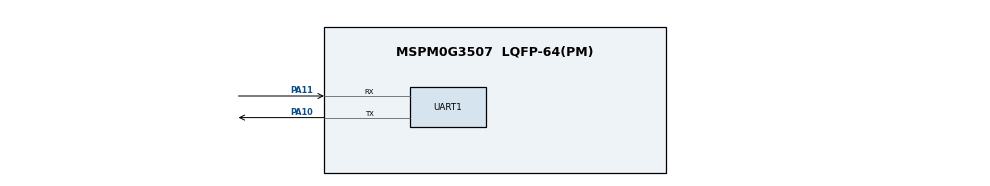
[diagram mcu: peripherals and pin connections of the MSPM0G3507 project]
/**
 * These arguments were used when this file was generated. They will be automatically applied on subsequent loads
 * via the GUI or CLI. Run CLI with '--help' for additional information on how to override these arguments.
 * @cliArgs --device "MSPM0G350X" --part "Default" --package "LQFP-64(PM)" --product "mspm0_sdk@2.02.00.05"
 * @v2CliArgs --device "MSPM0G3507" --package "LQFP-64(PM)" --product "mspm0_sdk@2.02.00.05"
 * @versions {"tool":"1.21.1+3772"}
 */

/**
 * Import the modules used in this configuration.
 */
const ADC12   = scripting.addModule("/ti/driverlib/ADC12", {}, false);
const ADC121  = ADC12.addInstance();
const SYSCTL  = scripting.addModule("/ti/driverlib/SYSCTL");
const SYSTICK = scripting.addModule("/ti/driverlib/SYSTICK");
const UART    = scripting.addModule("/ti/driverlib/UART", {}, false);
const UART1   = UART.addInstance();

/**
 * Write custom configuration values to the imported modules.
 */
ADC121.$name                             = "ADC_VOLTAGE";
ADC121.sampClkDiv                        = "DL_ADC12_CLOCK_DIVIDE_8";
ADC121.repeatMode                        = true;
ADC121.adcMem0_name                      = "ADC_CH0";
ADC121.powerDownMode                     = "DL_ADC12_POWER_DOWN_MODE_MANUAL";
ADC121.sampleTime0                       = "10 ms";
ADC121.enabledInterrupts                 = ["DL_ADC12_INTERRUPT_MEM0_RESULT_LOADED"];
ADC121.adcPin0Config.$name               = "ti_driverlib_gpio_GPIOPinGeneric0";
ADC121.adcPin0Config.hideOutputInversion = scripting.forceWrite(false);

const Board = scripting.addModule("/ti/driverlib/Board", {}, false);

SYSCTL.forceDefaultClkConfig = true;

SYSTICK.period = 32000;

UART1.$name                    = "UART_0";
UART1.peripheral.rxPin.$assign = "PA11";
UART1.peripheral.txPin.$assign = "PA10";
UART1.txPinConfig.$name        = "ti_driverlib_gpio_GPIOPinGeneric1";
UART1.rxPinConfig.$name        = "ti_driverlib_gpio_GPIOPinGeneric2";

/**
 * Pinmux solution for unlocked pins/peripherals. This ensures that minor changes to the automatic solver in a future
 * version of the tool will not impact the pinmux you originally saw.  These lines can be completely deleted in order to
 * re-solve from scratch.
 */
ADC121.peripheral.$suggestSolution         = "ADC0";
ADC121.peripheral.adcPin0.$suggestSolution = "PA27";
Board.peripheral.$suggestSolution          = "DEBUGSS";
Board.peripheral.swclkPin.$suggestSolution = "PA20";
Board.peripheral.swdioPin.$suggestSolution = "PA19";
SYSCTL.peripheral.$suggestSolution         = "SYSCTL";
UART1.peripheral.$suggestSolution          = "UART0";
